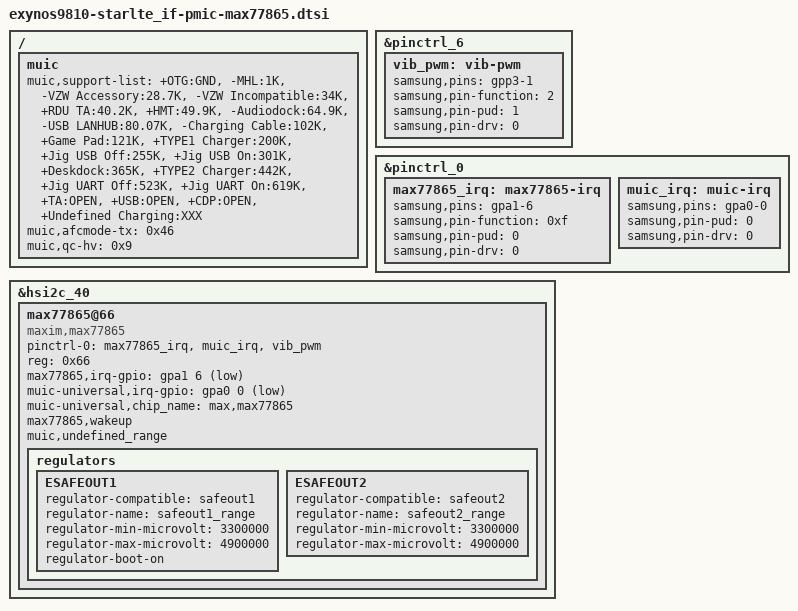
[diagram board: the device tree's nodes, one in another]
/*
 * SAMSUNG UNIVERSAL9810 board device tree source
 *
 * Copyright (c) 2017 Samsung Electronics Co., Ltd.
 *		http://www.samsung.com
 *
 * This program is free software; you can redistribute it and/or modify
 * it under the terms of the GNU General Public License version 2 as
 * published by the Free Software Foundation.
 */

/ {
	fragment@muic {
		target-path = "/";
		__overlay__ {
			muic {
				status = "okay";
				muic,support-list = "+OTG:GND",
					"-MHL:1K",
					"-VZW Accessory:28.7K",
					"-VZW Incompatible:34K",
					"+RDU TA:40.2K",
					"+HMT:49.9K",
					"-Audiodock:64.9K",
					"-USB LANHUB:80.07K",
					"-Charging Cable:102K",
					"+Game Pad:121K",
					"+TYPE1 Charger:200K",
					"+Jig USB Off:255K",
					"+Jig USB On:301K",
					"+Deskdock:365K",
					"+TYPE2 Charger:442K",
					"+Jig UART Off:523K",
					"+Jig UART On:619K",
					"+TA:OPEN",
					"+USB:OPEN",
					"+CDP:OPEN",
					"+Undefined Charging:XXX";
				muic,afcmode-tx = /bits/ 8 <0x46>;
				muic,qc-hv = /bits/ 8 <0x9>;
			};
		};
	};
};

&pinctrl_6 {
	vib_pwm: vib-pwm {
		samsung,pins = "gpp3-1";
		samsung,pin-function = <2>;
		samsung,pin-pud = <1>;
		samsung,pin-drv = <0>;
	};
};

&pinctrl_0 {
	max77865_irq: max77865-irq {
		samsung,pins = "gpa1-6";
		samsung,pin-function = <0xf>;
		samsung,pin-pud = <0>;
		samsung,pin-drv = <0>;
	};

	muic_irq: muic-irq {
		samsung,pins = "gpa0-0";
		samsung,pin-pud = <0>;
		samsung,pin-drv = <0>;
	};
};

&hsi2c_40 {
	#address-cells = <1>;
	#size-cells = <0>;
	status = "okay";
	max77865@66 {
		compatible = "maxim,max77865";
		pinctrl-names = "default";
		pinctrl-0 = <&max77865_irq &muic_irq &vib_pwm>;
		reg = <0x66>;
		max77865,irq-gpio = <&gpa1 6 1>;
		muic-universal,irq-gpio = <&gpa0 0 1>;
		muic-universal,chip_name = "max,max77865";
		max77865,wakeup;
		muic,undefined_range;

		regulators {
			ESAFEOUT1 {
				regulator-compatible = "safeout1";
				regulator-name = "safeout1_range";
				regulator-min-microvolt = <3300000>;
				regulator-max-microvolt = <4900000>;
				regulator-boot-on;
			};

			ESAFEOUT2 {
				regulator-compatible = "safeout2";
				regulator-name = "safeout2_range";
				regulator-min-microvolt = <3300000>;
				regulator-max-microvolt = <4900000>;
			};
		};
	};
};


